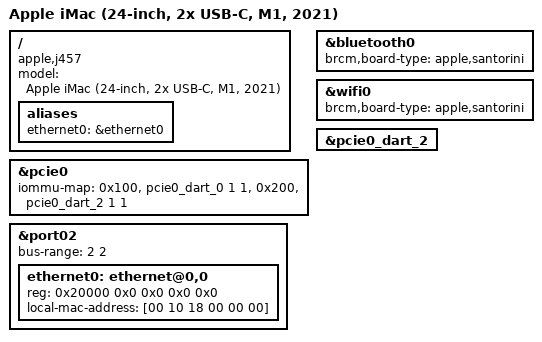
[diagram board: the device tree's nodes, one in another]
// SPDX-License-Identifier: GPL-2.0+ OR MIT
/*
 * Apple iMac (24-inch, 2x USB-C, M1, 2020)
 *
 * target-type: J457
 *
 * Copyright The Asahi Linux Contributors
 */

/dts-v1/;

#include "t8103.dtsi"
#include "t8103-jxxx.dtsi"

/ {
	compatible = "apple,j457", "apple,t8103", "apple,arm-platform";
	model = "Apple iMac (24-inch, 2x USB-C, M1, 2021)";

	aliases {
		ethernet0 = &ethernet0;
	};
};

/*
 * Adjust pcie0's iommu-map to account for the disabled port01.
 */
&pcie0 {
	iommu-map = <0x100 &pcie0_dart_0 1 1>,
			<0x200 &pcie0_dart_2 1 1>;
};

&bluetooth0 {
	brcm,board-type = "apple,santorini";
};

&wifi0 {
	brcm,board-type = "apple,santorini";
};

/*
 * Force the bus number assignments so that we can declare some of the
 * on-board devices and properties that are populated by the bootloader
 * (such as MAC addresses).
 */

&port02 {
	bus-range = <2 2>;
	status = "okay";
	ethernet0: ethernet@0,0 {
		reg = <0x20000 0x0 0x0 0x0 0x0>;
		/* To be filled by the loader */
		local-mac-address = [00 10 18 00 00 00];
	};
};

&pcie0_dart_2 {
	status = "okay";
};
